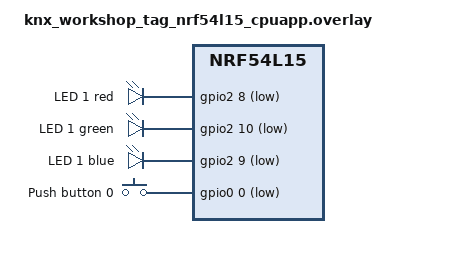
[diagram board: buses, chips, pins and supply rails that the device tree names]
/ {
	leds {
		compatible = "gpio-leds";

		led1_red: led1_red {
			gpios = <&gpio2 8 GPIO_ACTIVE_LOW>;
			label = "LED 1 red";
		};

		led1_green: led1_green {
			gpios = <&gpio2 10 GPIO_ACTIVE_LOW>;
			label = "LED 1 green";
		};

		led1_blue: led1_blue {
			gpios = <&gpio2 9 GPIO_ACTIVE_LOW>;
			label = "LED 1 blue";
		};
	};

	rgb_led_1: rgb_led_1 {
		compatible = "leds-group-multicolor";
		leds = <&led1_red>, <&led1_green>, <&led1_blue>;
		color-mapping = <LED_COLOR_ID_RED>, <LED_COLOR_ID_GREEN>, <LED_COLOR_ID_BLUE>;
	};

	buttons {
		compatible = "gpio-keys";

		button0: button0 {
			gpios = <&gpio0 0 (GPIO_PULL_UP | GPIO_ACTIVE_LOW)>;
			label = "Push button 0";
			zephyr,code = <INPUT_KEY_0>;
		};
	};
};
